VERSION ""

NS_ :

BS_:

BU_: receive send

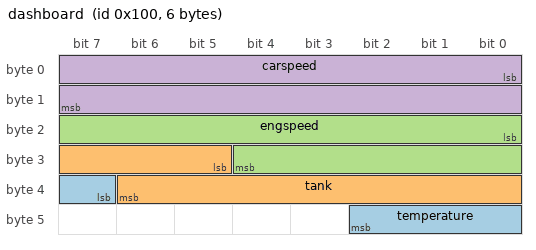
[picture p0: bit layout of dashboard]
BO_ 256 dashboard: 6 send
 SG_ temperature : 39|4@1+ (1,0) [0|15] "" Vector__XXX
 SG_ tank : 29|10@1+ (1,0) [0|0] ""  receive
 SG_ engspeed : 16|13@1+ (1,0) [0|0] ""  receive
 SG_ carspeed : 0|16@1+ (1,0) [0|0] ""  receive

EV_ evtemperaturetrans: 0 [0|0] "" 0 1 DUMMY_NODE_VECTOR0 Vector__XXX;

EV_ evtemperaturerec: 0 [0|0] "" 0 2 DUMMY_NODE_VECTOR0 Vector__XXX;

EV_ evengspeedrec: 0 [0|0] "" 0 3 DUMMY_NODE_VECTOR0  receive;

EV_ evcarspeedrec: 0 [0|0] "" 0 4 DUMMY_NODE_VECTOR0  receive;

EV_ evtankrec: 0 [0|0] "" 0 5 DUMMY_NODE_VECTOR0  receive;

EV_ evtanktrans: 0 [0|0] "" 0 6 DUMMY_NODE_VECTOR0  send;

EV_ evcarspeedtrans: 0 [0|0] "" 0 7 DUMMY_NODE_VECTOR0  send;

EV_ evengspeedtrans: 0 [0|0] "" 0 8 DUMMY_NODE_VECTOR0  send;
